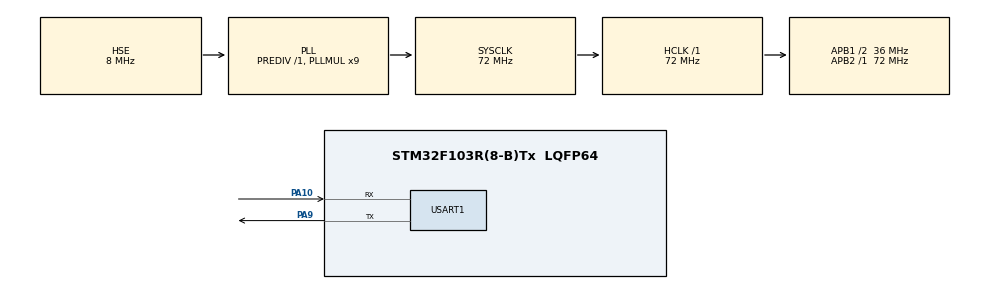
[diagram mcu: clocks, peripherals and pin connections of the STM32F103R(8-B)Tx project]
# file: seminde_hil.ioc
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Mcu.Family=STM32F1
Mcu.Name=STM32F103R(8-B)Tx
Mcu.Package=LQFP64
NVIC.PriorityGroup=NVIC_PRIORITYGROUP_4
NVIC.USART1_IRQn=true\:0\:0\:false\:false\:true
PA10.Mode=Asynchronous
PA10.Signal=USART1_RX
PA13.Mode=Trace_Asynchronous_SW
PA13.Signal=SYS_JTMS-SWDIO
PA14.Mode=Trace_Asynchronous_SW
PA14.Signal=SYS_JTCK-SWCLK
PA9.Mode=Asynchronous
PA9.Signal=USART1_TX
PB3.Mode=Trace_Asynchronous_SW
PB3.Signal=SYS_JTDO-TRACESWO
PD0-OSC_IN.Mode=HSE-External-Oscillator
PD0-OSC_IN.Signal=RCC_OSC_IN
PD1-OSC_OUT.Mode=HSE-External-Oscillator
PD1-OSC_OUT.Signal=RCC_OSC_OUT
ProjectManager.HeapSize=0x200
ProjectManager.StackSize=0x400
ProjectManager.TargetToolchain=MDK-ARM V5
RCC.AHBFreq_Value=72000000
RCC.APB1CLKDivider=RCC_HCLK_DIV2
RCC.APB1Freq_Value=36000000
RCC.APB1TimFreq_Value=72000000
RCC.APB2Freq_Value=72000000
RCC.APB2TimFreq_Value=72000000
RCC.HCLKFreq_Value=72000000
RCC.PLLMUL=RCC_PLL_MUL9
RCC.PLLSourceVirtual=RCC_PLLSOURCE_HSE
RCC.SYSCLKFreq_VALUE=72000000
RCC.SYSCLKSource=RCC_SYSCLKSOURCE_PLLCLK
RCC.USBFreq_Value=72000000
USART1.VirtualMode=VM_ASYNC
board=seminde_hil

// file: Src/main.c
/**
  ******************************************************************************
  * File Name          : main.c
  * Description        : Main program body
  ******************************************************************************
  ** This notice applies to any and all portions of this file
  * that are not between comment pairs USER CODE BEGIN and
  * USER CODE END. Other portions of this file, whether
  * inserted by the user or by software development tools
  * are owned by their respective copyright owners.
  *
  * COPYRIGHT(c) 2017 STMicroelectronics
  *
  * Redistribution and use in source and binary forms, with or without modification,
  * are permitted provided that the following conditions are met:
  *   1. Redistributions of source code must retain the above copyright notice,
  *      this list of conditions and the following disclaimer.
  *   2. Redistributions in binary form must reproduce the above copyright notice,
  *      this list of conditions and the following disclaimer in the documentation
  *      and/or other materials provided with the distribution.
  *   3. Neither the name of STMicroelectronics nor the names of its contributors
  *      may be used to endorse or promote products derived from this software
  *      without specific prior written permission.
  *
  * THIS SOFTWARE IS PROVIDED BY THE COPYRIGHT HOLDERS AND CONTRIBUTORS "AS IS"
  * AND ANY EXPRESS OR IMPLIED WARRANTIES, INCLUDING, BUT NOT LIMITED TO, THE
  * IMPLIED WARRANTIES OF MERCHANTABILITY AND FITNESS FOR A PARTICULAR PURPOSE ARE
  * DISCLAIMED. IN NO EVENT SHALL THE COPYRIGHT HOLDER OR CONTRIBUTORS BE LIABLE
  * FOR ANY DIRECT, INDIRECT, INCIDENTAL, SPECIAL, EXEMPLARY, OR CONSEQUENTIAL
  * DAMAGES (INCLUDING, BUT NOT LIMITED TO, PROCUREMENT OF SUBSTITUTE GOODS OR
  * SERVICES; LOSS OF USE, DATA, OR PROFITS; OR BUSINESS INTERRUPTION) HOWEVER
  * CAUSED AND ON ANY THEORY OF LIABILITY, WHETHER IN CONTRACT, STRICT LIABILITY,
  * OR TORT (INCLUDING NEGLIGENCE OR OTHERWISE) ARISING IN ANY WAY OUT OF THE USE
  * OF THIS SOFTWARE, EVEN IF ADVISED OF THE POSSIBILITY OF SUCH DAMAGE.
  *
  ******************************************************************************
  */
#include "main.h"
#include "stm32f1xx_hal.h"

/* USER CODE BEGIN Includes */

#include "string.h"
#include <hil_lib.h>

/* USER CODE END Includes */

UART_HandleTypeDef huart1;

/* USER CODE BEGIN PV */
/* Private variables ---------------------------------------------------------*/

// Buffer and index to control the data in UART1
uint8_t buffer_in[BUFFER_IN_SIZE];
uint32_t ind_buffer_in = 0;

volatile uint8_t newSentenceReady;			// Flag that control the writing on input buffer
volatile uint8_t num_comma;
volatile uint8_t checksum;
volatile uint8_t correct_msg;
volatile uint8_t input_state;

/* USER CODE END PV */

void SystemClock_Config(void);
static void MX_GPIO_Init(void);
static void MX_USART1_UART_Init(void);

/* USER CODE BEGIN PFP */
/* Private function prototypes -----------------------------------------------*/

/* USER CODE END PFP */

int main(void)

{

  /* MCU Configuration----------------------------------------------------------*/

  /* Reset of all peripherals, Initializes the Flash interface and the Systick. */
  HAL_Init();

  /* Configure the system clock */
  SystemClock_Config();

  /* Initialize all configured peripherals */
  MX_GPIO_Init();
  MX_USART1_UART_Init();

  /* USER CODE BEGIN 2 */

	__HAL_UART_ENABLE_IT(&huart1, UART_IT_RXNE);

	newSentenceReady = 0;
	num_comma = 0;
	checksum = 0;
	correct_msg = 0;
	input_state = 0;

  /* USER CODE END 2 */

  /* Infinite loop */
  /* USER CODE BEGIN WHILE */
  while (1)
  {

		if( newSentenceReady == 1 ){
			uint8_t strHilIn[DATA_IN_SIZE];
			uint8_t strHilOut[BUFFER_OUT_SIZE];

			// Clear the auxiliar IN buffer and copy on this the data that arrived
			memset( strHilIn, '\0', sizeof(strHilIn) );
			memcpy( strHilIn, buffer_in, DATA_IN_SIZE );
			//memset( UserTxBufferFS, '\0', sizeof(UserTxBufferFS));

			HIL_Calculate(strHilIn, strHilOut);

			HAL_UART_Transmit(&huart1, strHilOut, strlen(strHilOut), 1);

			HAL_Delay(10);

			newSentenceReady = 0;
		}

		//HAL_UART_Transmit(&huart1, buffer_out, strlen(buffer_out), 10);
		//HAL_Delay(1000);

  /* USER CODE END WHILE */

  }

}

/** System Clock Configuration
*/
void SystemClock_Config(void)
{

  RCC_OscInitTypeDef RCC_OscInitStruct;
  RCC_ClkInitTypeDef RCC_ClkInitStruct;

    /**Initializes the CPU, AHB and APB busses clocks
    */
  RCC_OscInitStruct.OscillatorType = RCC_OSCILLATORTYPE_HSE;
  RCC_OscInitStruct.HSEState = RCC_HSE_ON;
  RCC_OscInitStruct.HSEPredivValue = RCC_HSE_PREDIV_DIV1;
  RCC_OscInitStruct.HSIState = RCC_HSI_ON;
  RCC_OscInitStruct.PLL.PLLState = RCC_PLL_ON;
  RCC_OscInitStruct.PLL.PLLSource = RCC_PLLSOURCE_HSE;
  RCC_OscInitStruct.PLL.PLLMUL = RCC_PLL_MUL9;
  if (HAL_RCC_OscConfig(&RCC_OscInitStruct) != HAL_OK)
  {
    _Error_Handler(__FILE__, __LINE__);
  }

    /**Initializes the CPU, AHB and APB busses clocks
    */
  RCC_ClkInitStruct.ClockType = RCC_CLOCKTYPE_HCLK|RCC_CLOCKTYPE_SYSCLK
                              |RCC_CLOCKTYPE_PCLK1|RCC_CLOCKTYPE_PCLK2;
  RCC_ClkInitStruct.SYSCLKSource = RCC_SYSCLKSOURCE_PLLCLK;
  RCC_ClkInitStruct.AHBCLKDivider = RCC_SYSCLK_DIV1;
  RCC_ClkInitStruct.APB1CLKDivider = RCC_HCLK_DIV2;
  RCC_ClkInitStruct.APB2CLKDivider = RCC_HCLK_DIV1;

  if (HAL_RCC_ClockConfig(&RCC_ClkInitStruct, FLASH_LATENCY_2) != HAL_OK)
  {
    _Error_Handler(__FILE__, __LINE__);
  }

    /**Configure the Systick interrupt time
    */
  HAL_SYSTICK_Config(HAL_RCC_GetHCLKFreq()/1000);

    /**Configure the Systick
    */
  HAL_SYSTICK_CLKSourceConfig(SYSTICK_CLKSOURCE_HCLK);

  /* SysTick_IRQn interrupt configuration */
  HAL_NVIC_SetPriority(SysTick_IRQn, 0, 0);
}

/* USART1 init function */
static void MX_USART1_UART_Init(void)
{

  huart1.Instance = USART1;
  //huart1.Init.BaudRate = 9600;
  huart1.Init.BaudRate = 500000;
	huart1.Init.WordLength = UART_WORDLENGTH_8B;
  huart1.Init.StopBits = UART_STOPBITS_1;
  huart1.Init.Parity = UART_PARITY_NONE;
  huart1.Init.Mode = UART_MODE_TX_RX;
  huart1.Init.HwFlowCtl = UART_HWCONTROL_NONE;
  huart1.Init.OverSampling = UART_OVERSAMPLING_16;
  if (HAL_UART_Init(&huart1) != HAL_OK)
  {
    _Error_Handler(__FILE__, __LINE__);
  }

}

/** Configure pins as
        * Analog
        * Input
        * Output
        * EVENT_OUT
        * EXTI
*/
static void MX_GPIO_Init(void)
{

  /* GPIO Ports Clock Enable */
  __HAL_RCC_GPIOD_CLK_ENABLE();
  __HAL_RCC_GPIOA_CLK_ENABLE();
  __HAL_RCC_GPIOB_CLK_ENABLE();

}

/* USER CODE BEGIN 4 */

void USART1_IRQHandler(void)
{
  /* USER CODE BEGIN USART1_IRQn 0 */

	// Confere se a interrupção foi ativada pela flag rx_not_empty
	uint32_t tmp_flag = 0;
	tmp_flag = __HAL_UART_GET_FLAG(&huart1, UART_FLAG_RXNE);

	// Confere a flag e se ja existe uma sentença pronta
	if( tmp_flag != 0 && newSentenceReady == 0 ){

		char chr_in;
		HAL_UART_Receive(&huart1, &chr_in, 1, 0);

		buffer_in[ind_buffer_in++] = chr_in;

		if( ind_buffer_in > DATA_IN_SIZE-1 ){

			if( HIL_CheckString(buffer_in) == 1 ){
				newSentenceReady = 1;

			}

			ind_buffer_in = 0;
		}
	}

  /* USER CODE END USART1_IRQn 10 */

	HAL_UART_IRQHandler(&huart1);

	/* USER CODE BEGIN USART1_IRQn 1 */

  /* USER CODE END USART1_IRQn 1 */
}

/* USER CODE END 4 */

void _Error_Handler(char * file, int line)
{
  while(1)
  {
  }
}

/************************ (C) COPYRIGHT STMicroelectronics *****END OF FILE****/
